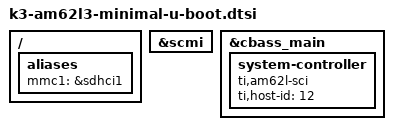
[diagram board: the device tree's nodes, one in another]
// SPDX-License-Identifier: GPL-2.0
/*
 * Copyright (C) 2025 Texas Instruments Incorporated - https://www.ti.com/
 */

#include "k3-am62l3-evm-binman.dtsi"

/ {
	aliases {
		mmc1 = &sdhci1;
	};
};

&scmi {
	bootph-all;
};

&cbass_main {
	system-controller {
		compatible = "ti,am62l-sci";
		ti,host-id = <12>;
		bootph-all;
	};
};
